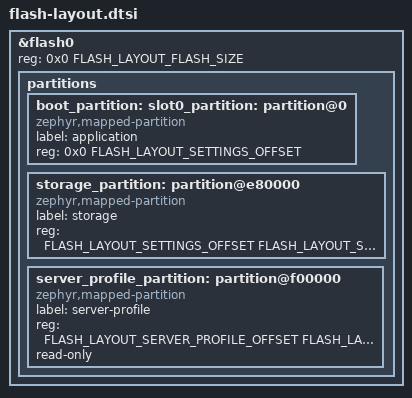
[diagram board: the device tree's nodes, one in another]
/*
 * Project flash layout of the 16 MB module (Nico, flash layout decision, 4 November 2026):
 * settings and the server profile image each have a fixed start and their own size, with
 * unassigned growth room behind each. The application gets everything before the settings.
 * storage.c checks that settings end before the server profile start, that the server profile
 * keeps its fixed start and ends within the flash, and that the largest server profile image fits.
 *
 * Unit addresses cannot be computed; dtc's unit_address_vs_reg check rejects a node name
 * that no longer matches its reg.
 */

#define FLASH_LAYOUT_FLASH_SIZE          DT_SIZE_M(16)
#define FLASH_LAYOUT_SETTINGS_OFFSET     0xE80000
#define FLASH_LAYOUT_SETTINGS_SIZE       DT_SIZE_K(192)
/* Fixed across firmware versions: a firmware update must still find the image flashed before it. */
#define FLASH_LAYOUT_SERVER_PROFILE_OFFSET 0xF00000
#define FLASH_LAYOUT_SERVER_PROFILE_SIZE   DT_SIZE_K(192)

&flash0
{
    reg = <0x0 FLASH_LAYOUT_FLASH_SIZE>;
    ranges = <0x0 0x0 FLASH_LAYOUT_FLASH_SIZE>;

    /* The board's 4 MB table also holds MCUboot, second-image, second-core and core-dump partitions. */
    /delete-node/ partitions;

    partitions
    {
        ranges;
        #address-cells = <1>;
        #size-cells = <1>;

        /* Simple Boot reads the image header at boot_partition, so that label stays on the application. */
        boot_partition: slot0_partition: partition@0
        {
            compatible = "zephyr,mapped-partition";
            label = "application";
            reg = <0x0 FLASH_LAYOUT_SETTINGS_OFFSET>;
        };

        storage_partition: partition@e80000
        {
            compatible = "zephyr,mapped-partition";
            label = "storage";
            reg = <FLASH_LAYOUT_SETTINGS_OFFSET FLASH_LAYOUT_SETTINGS_SIZE>;
        };

        /* Written only by tools/flash-server-profile.ps1. */
        server_profile_partition: partition@f00000
        {
            compatible = "zephyr,mapped-partition";
            label = "server-profile";
            reg = <FLASH_LAYOUT_SERVER_PROFILE_OFFSET FLASH_LAYOUT_SERVER_PROFILE_SIZE>;
            read-only;
        };
    };
};
